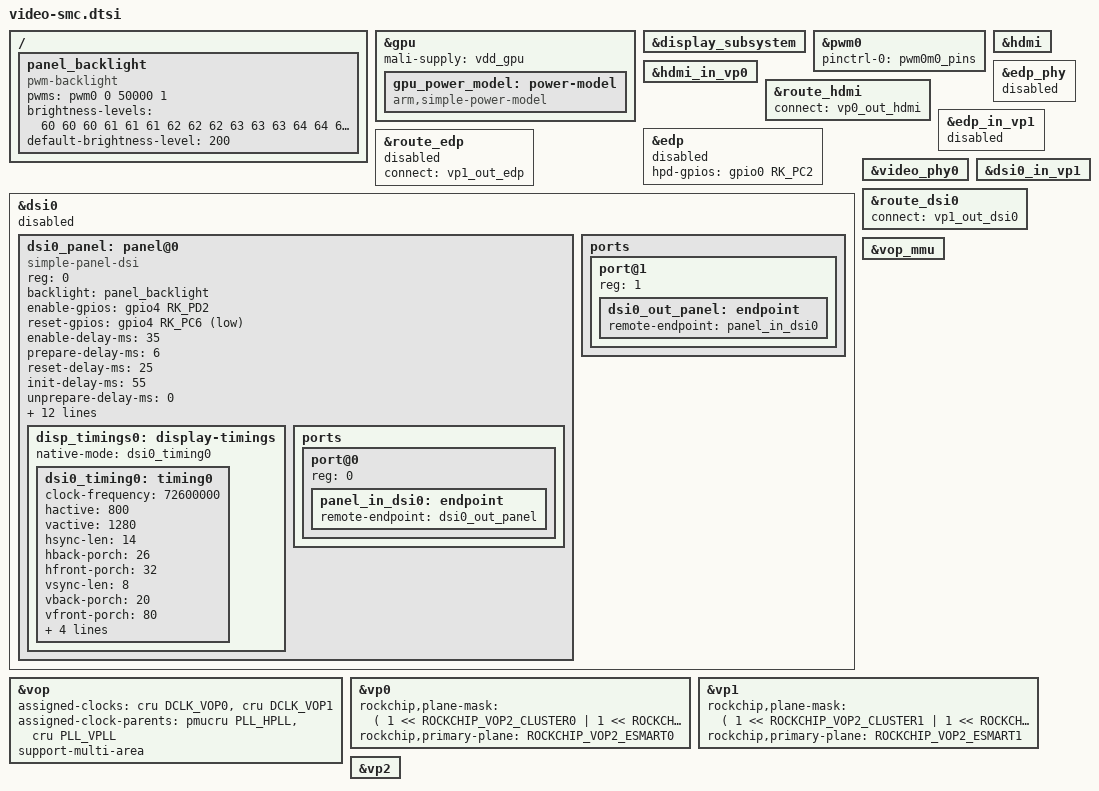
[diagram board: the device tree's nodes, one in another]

#include <dt-bindings/display/rockchip_vop.h>
#include <dt-bindings/display/drm_mipi_dsi.h>

/{
	panel_backlight: panel_backlight {
		status = "okay";
		compatible = "pwm-backlight";

		// Backlight doesn't use enable pin
		// LCD_BKLT_EN
		//enable-gpios = <&gpio4 RK_PD1 GPIO_ACTIVE_HIGH>;

		// LCD_PWM (pwm0_m0)
		// pwm0:PWM number   0 5000000:PWM period in nanoseconds  1:polarity
		pwms = <&pwm0 0 50000 1>;
		brightness-levels = <
				60  60  60  61  61  61  62  62
				62  63  63  63  64  64  64  65
				65  65  66  66  66  67  67  67
				68  68  68  69  69  69  70  70
				70  71  71  71  72  72  72  73
				73  73  74  74  74  75  75  75
				76  76  76  77  77  77  78  78
				78  79  79  79  80  80  80  81
				81  81  82  82  82  83  83  83
				84  84  84  85  85  85  86  86
				86  87  87  87  88  88  88  89
				89  89  90  91  92  93  94  95
				96  97  98  99 100 101 102 103
				104 105 106 107 108 109 110 111
				112 113 114 115 116 117 118 119
				120 121 122 123 124 125 126 127
				128 129 130 131 132 133 134 135
				136 137 138 139 140 141 142 143
				144 145 146 147 148 149 150 151
				152 153 154 155 156 157 158 159
				160 161 162 163 164 165 166 167
				168 169 170 171 172 173 174 175
				176 177 178 179 180 181 182 183
				184 185 186 187 188 189 190 191
				192 193 194 195 196 197 198 199
				200 201 202 203 204 205 206 207
				208 209 210 211 212 213 214 215
				216 217 218 219 220 221 222 223
				224 225 226 227 228 229 230 231
				232 233 234 235 236 237 238 239
				240 241 242 243 244 245 246 247
				248 249 250 251 252 253 254 255
			>;
		default-brightness-level = <200>;
	};
};

&gpu {
	mali-supply = <&vdd_gpu>;
	status = "okay";
	gpu_power_model: power-model {
		compatible = "arm,simple-power-model";
	};
};

&display_subsystem {
	status = "okay";
};

&pwm0 {
	pinctrl-names = "active";
	pinctrl-0 = <&pwm0m0_pins>;
	status = "okay";
};

//***************************************************************************************//

&hdmi {
	status = "okay";
};

&hdmi_in_vp0 {
	status = "okay";
};

&route_hdmi {
	status = "okay";
	connect = <&vp0_out_hdmi>;
};

//***************************************************************************************//

&edp {
/*
	CPU_DP_HDP
*/
	hpd-gpios = <&gpio0 RK_PC2 GPIO_ACTIVE_HIGH>;
	status = "disabled";
};

&edp_phy  {
	status = "disabled";
};

// VP1 is multiplexed with DSI0
&edp_in_vp1 {
//&edp_in_vp0 {
	status = "disabled";
};

&route_edp {
	// VP1 is multiplexed with DSI0
	connect = <&vp1_out_edp>;
	//connect = <&vp0_out_edp>;
	status = "disabled";
};

//***************************************************************************************//

&dsi0 {
	status = "disabled";
	//rockchip,lane-rate = <1000>;
	dsi0_panel: panel@0 {
		status = "okay";
		compatible = "simple-panel-dsi";
		reg = <0>;
		backlight = <&panel_backlight>;

		// LCD_VDD_EN
		enable-gpios = <&gpio4 RK_PD2 GPIO_ACTIVE_HIGH>;
		// GPIO4_SPI3_CS_
		reset-gpios = <&gpio4 RK_PC6 GPIO_ACTIVE_LOW>;

		enable-delay-ms = <35>;
		prepare-delay-ms = <6>;
		reset-delay-ms = <25>;
		init-delay-ms = <55>;
		unprepare-delay-ms = <0>;
		disable-delay-ms = <20>;
		mipi-data-delay-ms = <200>;
		size,width = <120>;
		size,height = <170>;
		dsi,flags = <(MIPI_DSI_MODE_VIDEO | MIPI_DSI_MODE_VIDEO_BURST | MIPI_DSI_MODE_LPM | MIPI_DSI_MODE_EOT_PACKET)>;
		dsi,format = <MIPI_DSI_FMT_RGB888>;
		dsi,lanes  = <4>;

		panel-init-sequence = [
				//39 00 04 B9 83 10 2E
				// 15 00 02 CF FF
				05 78 01 11
				05 32 01 29
				//15 00 02 35 00
			];

		panel-exit-sequence = [
				05 00 01 28
				05 00 01 10
			];

		disp_timings0: display-timings {
			native-mode = <&dsi0_timing0>;
			dsi0_timing0: timing0 {
				clock-frequency = <72600000>;//<80000000>;
				hactive = <800>;//<768>;
				vactive = <1280>;
				hsync-len = <14>;   //20, 50,10
				hback-porch = <26>; //50, 56,10
				hfront-porch = <32>;//50, 30,180
				vsync-len = <8>;//4
				vback-porch = <20>;//4
				vfront-porch = <80>;//8
				hsync-active = <0>;
				vsync-active = <0>;
				de-active = <0>;
				pixelclk-active = <0>;
			};
		};

		ports {
			#address-cells = <1>;
			#size-cells = <0>;

			port@0 {
				reg = <0>;
					panel_in_dsi0: endpoint {
					remote-endpoint = <&dsi0_out_panel>;
				};
			};
		};
	};

	ports {
		#address-cells = <1>;
		#size-cells = <0>;

		port@1 {
		reg = <1>;
			dsi0_out_panel: endpoint {
				remote-endpoint = <&panel_in_dsi0>;
			};
		};
	};
};

&video_phy0 {
	status = "okay";
};

// Port is multiplexed with EDP
&dsi0_in_vp1 {
	status = "okay";
};

&route_dsi0 {
	// Port is multiplexed with EDP
	connect = <&vp1_out_dsi0>;
	status = "okay";
};

//***************************************************************************************//

&vop {
	status = "okay";
	assigned-clocks = <&cru DCLK_VOP0>, <&cru DCLK_VOP1>;
	assigned-clock-parents = <&pmucru PLL_HPLL>, <&cru PLL_VPLL>;
	support-multi-area;
	//disable-afbc-win;
};

&vop_mmu {
	status = "okay";
};

// VP0 works with DSI0, DSI1, HDMI, EDP
&vp0 {
	rockchip,plane-mask = <( 1 << ROCKCHIP_VOP2_CLUSTER0 | 1 << ROCKCHIP_VOP2_ESMART0 )>;
	rockchip,primary-plane = <ROCKCHIP_VOP2_ESMART0>;
//	cursor-win-id = <ROCKCHIP_VOP2_SMART0>;
};

// VP1 works with DSI0, DSI1, HDMI, EDP, LVDS
&vp1 {
	rockchip,plane-mask = <( 1 << ROCKCHIP_VOP2_CLUSTER1 | 1 << ROCKCHIP_VOP2_ESMART1 )>;
	rockchip,primary-plane = <ROCKCHIP_VOP2_ESMART1>;
//	cursor-win-id = <ROCKCHIP_VOP2_SMART0>;
};

// VP2 works with LVDS, RGB
&vp2 {
//	rockchip,plane-mask = <( 1 << ROCKCHIP_VOP2_CLUSTER2 | 1 << ROCKCHIP_VOP2_ESMART2 )>;
//	rockchip,primary-plane = <ROCKCHIP_VOP2_ESMART2>;
};
